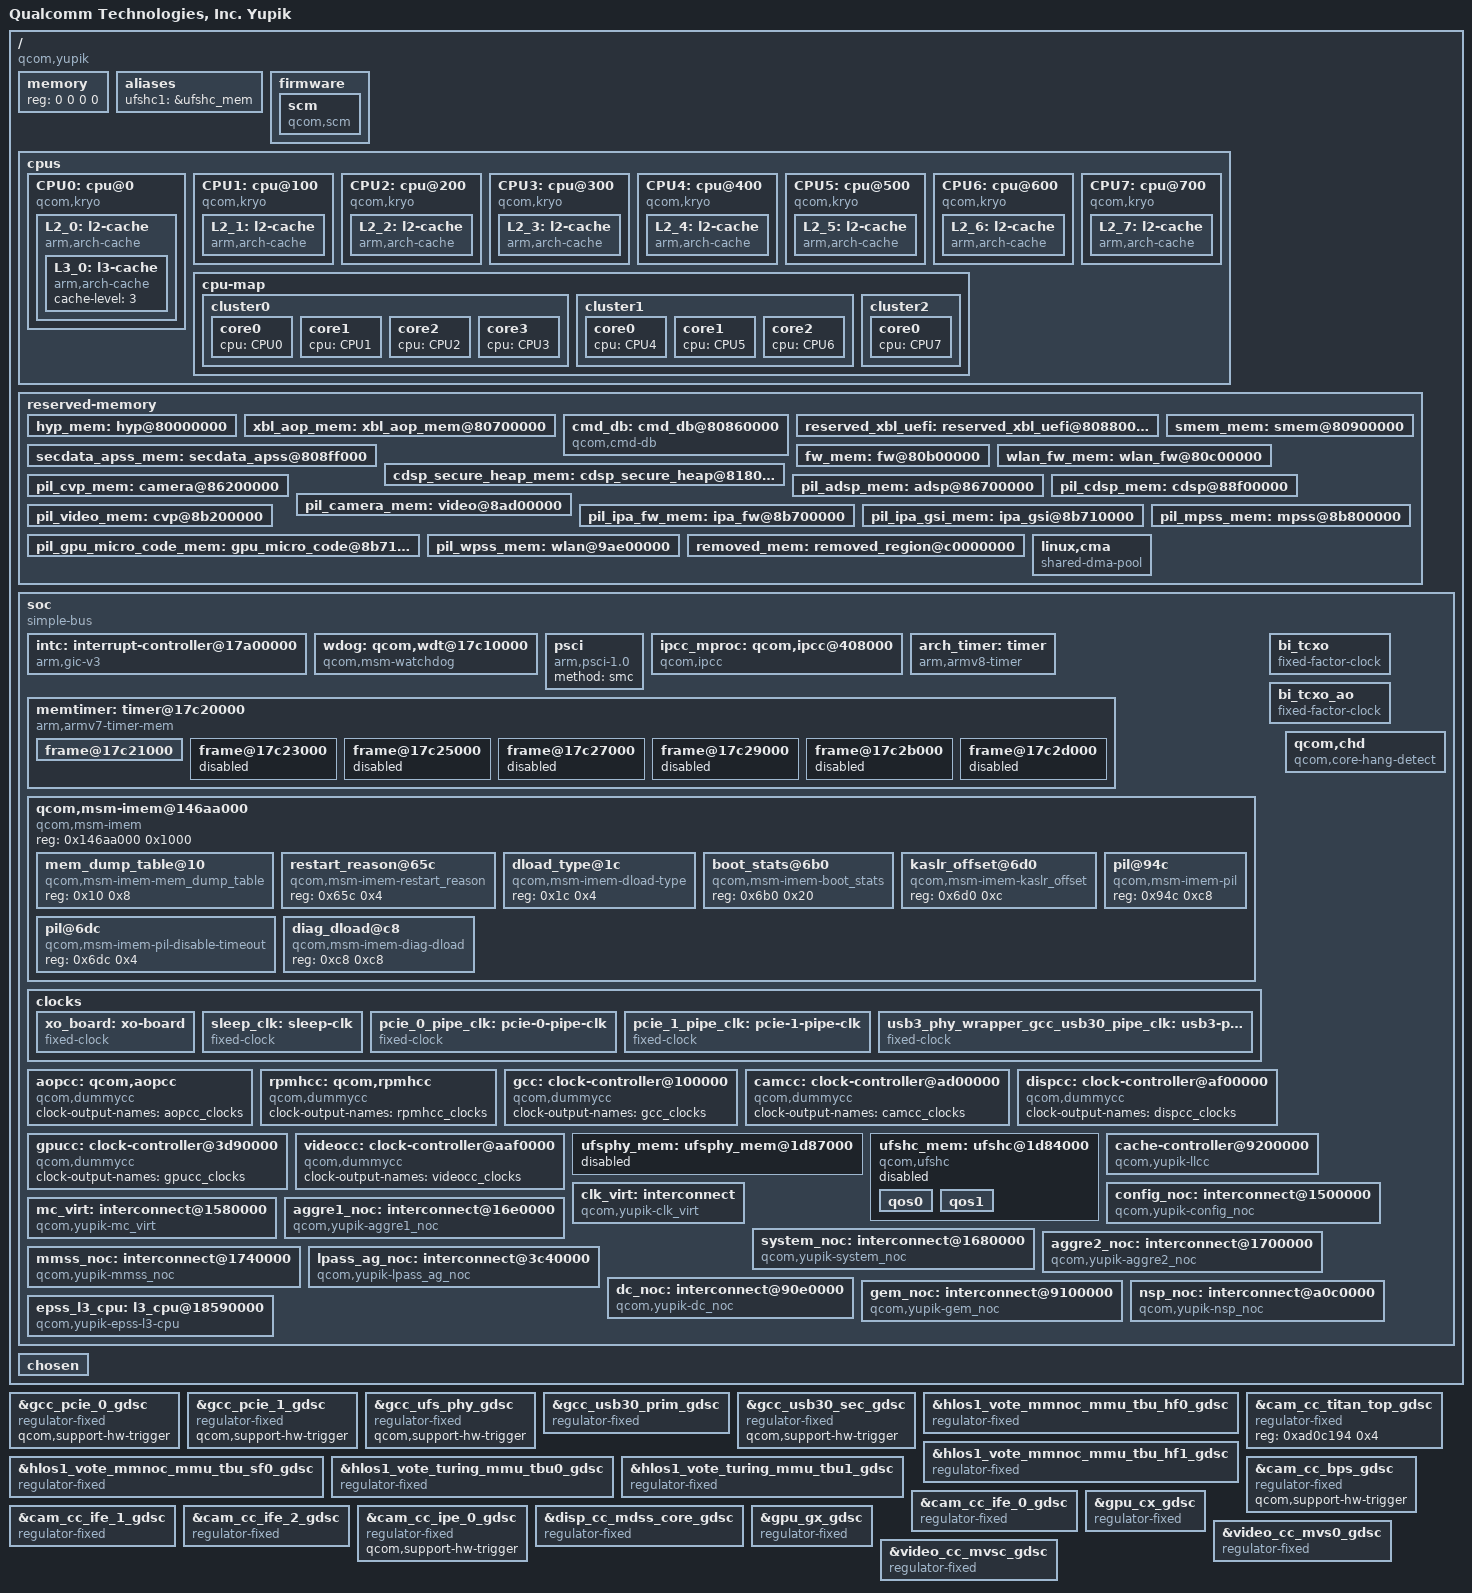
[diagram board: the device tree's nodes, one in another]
#include <dt-bindings/clock/qcom,aop-qmp.h>
#include <dt-bindings/clock/qcom,camcc-yupik.h>
#include <dt-bindings/clock/qcom,dispcc-yupik.h>
#include <dt-bindings/clock/qcom,gcc-yupik.h>
#include <dt-bindings/clock/qcom,gpucc-yupik.h>
#include <dt-bindings/clock/qcom,rpmh.h>
#include <dt-bindings/clock/qcom,videocc-yupik.h>
#include <dt-bindings/interconnect/qcom,epss-l3.h>
#include <dt-bindings/interconnect/qcom,icc.h>
#include <dt-bindings/interconnect/qcom,yupik.h>
#include <dt-bindings/interrupt-controller/arm-gic.h>
#include <dt-bindings/soc/qcom,ipcc.h>
#include <dt-bindings/gpio/gpio.h>

/ {
	model = "Qualcomm Technologies, Inc. Yupik";
	compatible = "qcom,yupik";
	qcom,msm-id = <475 0x10000>;
	interrupt-parent = <&intc>;

	#address-cells = <2>;
	#size-cells = <2>;
	memory { device_type = "memory"; reg = <0 0 0 0>; };

	aliases {
		ufshc1 = &ufshc_mem; /* Embedded UFS Slot */
	};

	firmware: firmware {
		scm {
			compatible = "qcom,scm";
		};
	};

	cpus {
		#address-cells = <2>;
		#size-cells = <0>;

		CPU0: cpu@0 {
			device_type = "cpu";
			compatible = "qcom,kryo";
			reg = <0x0 0x0>;
			enable-method = "psci";
			next-level-cache = <&L2_0>;
			L2_0: l2-cache {
			      compatible = "arm,arch-cache";
			      cache-level = <2>;
			      next-level-cache = <&L3_0>;

				L3_0: l3-cache {
				      compatible = "arm,arch-cache";
				      cache-level = <3>;
				};
			};
		};

		CPU1: cpu@100 {
			device_type = "cpu";
			compatible = "qcom,kryo";
			reg = <0x0 0x100>;
			enable-method = "psci";
			next-level-cache = <&L2_1>;
			L2_1: l2-cache {
			      compatible = "arm,arch-cache";
			      cache-level = <2>;
			      next-level-cache = <&L3_0>;
			};
		};

		CPU2: cpu@200 {
			device_type = "cpu";
			compatible = "qcom,kryo";
			reg = <0x0 0x200>;
			enable-method = "psci";
			next-level-cache = <&L2_2>;
			L2_2: l2-cache {
			      compatible = "arm,arch-cache";
			      cache-level = <2>;
			      next-level-cache = <&L3_0>;
			};
		};

		CPU3: cpu@300 {
			device_type = "cpu";
			compatible = "qcom,kryo";
			reg = <0x0 0x300>;
			enable-method = "psci";
			next-level-cache = <&L2_3>;
			L2_3: l2-cache {
			      compatible = "arm,arch-cache";
			      cache-level = <2>;
			      next-level-cache = <&L3_0>;
			};
		};

		CPU4: cpu@400 {
			device_type = "cpu";
			compatible = "qcom,kryo";
			reg = <0x0 0x400>;
			enable-method = "psci";
			next-level-cache = <&L2_4>;
			L2_4: l2-cache {
			      compatible = "arm,arch-cache";
			      cache-level = <2>;
			      next-level-cache = <&L3_0>;
			};
		};

		CPU5: cpu@500 {
			device_type = "cpu";
			compatible = "qcom,kryo";
			reg = <0x0 0x500>;
			enable-method = "psci";
			next-level-cache = <&L2_5>;
			L2_5: l2-cache {
			      compatible = "arm,arch-cache";
			      cache-level = <2>;
			      next-level-cache = <&L3_0>;
			};
		};

		CPU6: cpu@600 {
			device_type = "cpu";
			compatible = "qcom,kryo";
			reg = <0x0 0x600>;
			enable-method = "psci";
			next-level-cache = <&L2_6>;
			L2_6: l2-cache {
			      compatible = "arm,arch-cache";
			      cache-level = <2>;
			      next-level-cache = <&L3_0>;
			};
		};

		CPU7: cpu@700 {
			device_type = "cpu";
			compatible = "qcom,kryo";
			reg = <0x0 0x700>;
			enable-method = "psci";
			next-level-cache = <&L2_7>;
			L2_7: l2-cache {
			      compatible = "arm,arch-cache";
			      cache-level = <2>;
			      next-level-cache = <&L3_0>;
			};
		};

		cpu-map {
			cluster0 {
				core0 {
					cpu = <&CPU0>;
				};

				core1 {
					cpu = <&CPU1>;
				};

				core2 {
					cpu = <&CPU2>;
				};

				core3 {
					cpu = <&CPU3>;
				};
			};

			cluster1 {
				core0 {
					cpu = <&CPU4>;
				};

				core1 {
					cpu = <&CPU5>;
				};

				core2 {
					cpu = <&CPU6>;
				};
			};

			cluster2 {

				core0 {
					cpu = <&CPU7>;
				};
			};
		};
	};

	reserved-memory {
		#address-cells = <2>;
		#size-cells = <2>;
		ranges;

		hyp_mem: hyp@80000000 {
			no-map;
			reg = <0x0 0x80000000 0x0 0x600000>;
		};

		xbl_aop_mem: xbl_aop_mem@80700000 {
			no-map;
			reg = <0x0 0x80700000 0x0 0x160000>;
		};

		cmd_db: cmd_db@80860000 {
			compatible = "qcom,cmd-db";
			no-map;
			reg = <0x0 0x80860000 0x0 0x20000>;
		};

		reserved_xbl_uefi: reserved_xbl_uefi@80880000 {
			no-map;
			reg = <0x0 0x80880000 0x0 0x14000>;
		};

		secdata_apss_mem: secdata_apss@808ff000 {
			no-map;
			reg = <0x0 0x808ff000 0x0 0x1000>;
		};

		smem_mem: smem@80900000 {
			no-map;
			reg = <0x0 0x80900000 0x0 0x200000>;
		};

		fw_mem: fw@80b00000 {
			no-map;
			reg = <0x0 0x80b00000 0x0 0x100000>;
		};

		wlan_fw_mem: wlan_fw@80c00000 {
			no-map;
			reg = <0x0 0x80c00000 0x0 0xc00000>;
		};

		cdsp_secure_heap_mem: cdsp_secure_heap@81800000 {
			no-map;
			reg = <0x0 0x81800000 0x0 0x1e00000>;
		};

		pil_cvp_mem: camera@86200000 {
			no-map;
			reg = <0x0 0x86200000 0x0 0x500000>;
		};

		pil_adsp_mem: adsp@86700000 {
			no-map;
			reg = <0x0 0x86700000 0x0 0x2800000>;
		};

		pil_cdsp_mem: cdsp@88f00000 {
			no-map;
			reg = <0x0 0x88f00000 0x0 0x1e00000>;
		};

		pil_camera_mem: video@8ad00000 {
			no-map;
			reg = <0x0 0x8ad00000 0x0 0x500000>;
		};

		pil_video_mem: cvp@8b200000 {
			no-map;
			reg = <0x0 0x8b200000 0x0 0x500000>;
		};

		pil_ipa_fw_mem: ipa_fw@8b700000 {
			no-map;
			reg = <0x0 0x8b700000 0x0 0x10000>;
		};

		pil_ipa_gsi_mem: ipa_gsi@8b710000 {
			no-map;
			reg = <0x0 0x8b710000 0x0 0xa000>;
		};

		pil_gpu_micro_code_mem: gpu_micro_code@8b71a000 {
			no-map;
			reg = <0x0 0x8b71a000 0x0 0x2000>;
		};

		pil_mpss_mem: mpss@8b800000 {
			no-map;
			reg = <0x0 0x8b800000 0x0 0xf600000>;
		};

		pil_wpss_mem: wlan@9ae00000 {
			no-map;
			reg = <0x0 0x9ae00000 0x0 0x1900000>;
		};

		removed_mem: removed_region@c0000000 {
			no-map;
			reg = <0x0 0xc0000000 0x0 0x5100000>;
		};

		/* global autoconfigured region for contiguous allocations */
		linux,cma {
			compatible = "shared-dma-pool";
			alloc-ranges = <0x0 0x00000000 0x0 0xffffffff>;
			reusable;
			alignment = <0x0 0x400000>;
			size = <0x0 0x2000000>;
			linux,cma-default;
		};
	};

	soc: soc { };

	chosen { };
};

&soc {
	#address-cells = <1>;
	#size-cells = <1>;
	ranges = <0 0 0 0xffffffff>;
	compatible = "simple-bus";

	intc: interrupt-controller@17a00000 {
		compatible = "arm,gic-v3";
		#interrupt-cells = <3>;
		interrupt-controller;
		#redistributor-regions = <1>;
		redistributor-stride = <0x0 0x20000>;
		reg = <0x17a00000 0x10000>,     /* GICD */
		      <0x17a60000 0x100000>;    /* GICR * 8 */
		interrupts = <GIC_PPI 9 IRQ_TYPE_LEVEL_LOW>;
	};

	wdog: qcom,wdt@17c10000 {
		compatible = "qcom,msm-watchdog";
		reg = <0x17c10000 0x1000>;
		reg-names = "wdt-base";
		interrupts = <GIC_SPI 0 IRQ_TYPE_LEVEL_HIGH>;
	};

	psci {
		compatible = "arm,psci-1.0";
		method = "smc";
	};

	ipcc_mproc: qcom,ipcc@408000 {
		compatible = "qcom,ipcc";
		reg = <0x408000 0x1000>;
		interrupts = <GIC_SPI 229 IRQ_TYPE_LEVEL_HIGH>;
		interrupt-controller;
		#interrupt-cells = <3>;
		#mbox-cells = <2>;
	};

	arch_timer: timer {
		compatible = "arm,armv8-timer";
		interrupts = <GIC_PPI 13 (GIC_CPU_MASK_SIMPLE(8) | IRQ_TYPE_LEVEL_LOW)>,
			     <GIC_PPI 14 (GIC_CPU_MASK_SIMPLE(8) | IRQ_TYPE_LEVEL_LOW)>,
			     <GIC_PPI 11 (GIC_CPU_MASK_SIMPLE(8) | IRQ_TYPE_LEVEL_LOW)>,
			     <GIC_PPI 12 (GIC_CPU_MASK_SIMPLE(8) | IRQ_TYPE_LEVEL_LOW)>;
		clock-frequency = <19200000>;
	};

	memtimer: timer@17c20000 {
		#address-cells = <1>;
		#size-cells = <1>;
		ranges;
		compatible = "arm,armv7-timer-mem";
		reg = <0x17c20000 0x1000>;
		clock-frequency = <19200000>;

		frame@17c21000 {
			frame-number = <0>;
			interrupts = <GIC_SPI 8 IRQ_TYPE_LEVEL_HIGH>,
				     <GIC_SPI 6 IRQ_TYPE_LEVEL_HIGH>;
			reg = <0x17c21000 0x1000>,
			      <0x17c22000 0x1000>;
		};

		frame@17c23000 {
			frame-number = <1>;
			interrupts = <GIC_SPI 9 IRQ_TYPE_LEVEL_HIGH>;
			reg = <0x17c23000 0x1000>;
			status = "disabled";
		};

		frame@17c25000 {
			frame-number = <2>;
			interrupts = <GIC_SPI 10 IRQ_TYPE_LEVEL_HIGH>;
			reg = <0x17c25000 0x1000>;
			status = "disabled";
		};

		frame@17c27000 {
			frame-number = <3>;
			interrupts = <GIC_SPI 11 IRQ_TYPE_LEVEL_HIGH>;
			reg = <0x17c27000 0x1000>;
			status = "disabled";
		};

		frame@17c29000 {
			frame-number = <4>;
			interrupts = <GIC_SPI 12 IRQ_TYPE_LEVEL_HIGH>;
			reg = <0x17c29000 0x1000>;
			status = "disabled";
		};

		frame@17c2b000 {
			frame-number = <5>;
			interrupts = <GIC_SPI 13 IRQ_TYPE_LEVEL_HIGH>;
			reg = <0x17c2b000 0x1000>;
			status = "disabled";
		};

		frame@17c2d000 {
			frame-number = <6>;
			interrupts = <GIC_SPI 14 IRQ_TYPE_LEVEL_HIGH>;
			reg = <0x17c2d000 0x1000>;
			status = "disabled";
		};
	};

	qcom,msm-imem@146aa000 {
		compatible = "qcom,msm-imem";
		reg = <0x146aa000 0x1000>;
		ranges = <0x0 0x146aa000 0x1000>;
		#address-cells = <1>;
		#size-cells = <1>;

		mem_dump_table@10 {
			compatible = "qcom,msm-imem-mem_dump_table";
			reg = <0x10 0x8>;
		};

		restart_reason@65c {
			compatible = "qcom,msm-imem-restart_reason";
			reg = <0x65c 0x4>;
		};

		dload_type@1c {
			compatible = "qcom,msm-imem-dload-type";
			reg = <0x1c 0x4>;
		};

		boot_stats@6b0 {
			compatible = "qcom,msm-imem-boot_stats";
			reg = <0x6b0 0x20>;
		};

		kaslr_offset@6d0 {
			compatible = "qcom,msm-imem-kaslr_offset";
			reg = <0x6d0 0xc>;
		};

		pil@94c {
			compatible = "qcom,msm-imem-pil";
			reg = <0x94c 0xc8>;
		};

		pil@6dc {
			compatible = "qcom,msm-imem-pil-disable-timeout";
			reg = <0x6dc 0x4>;
		};

		diag_dload@c8 {
			compatible = "qcom,msm-imem-diag-dload";
			reg = <0xc8 0xc8>;
		};
	};

	clocks {
		xo_board: xo-board {
			compatible = "fixed-clock";
			clock-frequency = <76800000>;
			clock-output-names = "xo_board";
			#clock-cells = <0>;
		};

		sleep_clk: sleep-clk {
			compatible = "fixed-clock";
			clock-frequency = <32000>;
			clock-output-names = "sleep_clk";
			#clock-cells = <0>;
		};

		pcie_0_pipe_clk: pcie-0-pipe-clk {
			compatible = "fixed-clock";
			clock-frequency = <1000>;
			clock-output-names = "pcie_0_pipe_clk";
			#clock-cells = <0>;
		};

		pcie_1_pipe_clk: pcie-1-pipe-clk {
			compatible = "fixed-clock";
			clock-frequency = <1000>;
			clock-output-names = "pcie_1_pipe_clk";
			#clock-cells = <0>;
		};

		usb3_phy_wrapper_gcc_usb30_pipe_clk: usb3-phy-wrapper-gcc-usb30-pipe-clk {
			compatible = "fixed-clock";
			clock-frequency = <1000>;
			clock-output-names = "usb3_phy_wrapper_gcc_usb30_pipe_clk";
			#clock-cells = <0>;
		};
	};

	bi_tcxo: bi_tcxo {
		compatible = "fixed-factor-clock";
		clock-mult = <1>;
		clock-div = <4>;
		clocks = <&xo_board>;
		#clock-cells = <0>;
	};

	bi_tcxo_ao: bi_tcxo_ao {
		compatible = "fixed-factor-clock";
		clock-mult = <1>;
		clock-div = <4>;
		clocks = <&xo_board>;
		#clock-cells = <0>;
	};

	aopcc: qcom,aopcc {
		compatible = "qcom,dummycc";
		clock-output-names = "aopcc_clocks";
		#clock-cells = <1>;
		#reset-cells = <1>;
	};

	rpmhcc: qcom,rpmhcc {
		compatible = "qcom,dummycc";
		clock-output-names = "rpmhcc_clocks";
		#clock-cells = <1>;
		#reset-cells = <1>;
	};

	gcc: clock-controller@100000 {
		compatible = "qcom,dummycc";
		clock-output-names = "gcc_clocks";
		#clock-cells = <1>;
		#reset-cells = <1>;
	};

	camcc: clock-controller@ad00000 {
		compatible = "qcom,dummycc";
		clock-output-names = "camcc_clocks";
		#clock-cells = <1>;
		#reset-cells = <1>;
	};

	dispcc: clock-controller@af00000 {
		compatible = "qcom,dummycc";
		clock-output-names = "dispcc_clocks";
		#clock-cells = <1>;
		#reset-cells = <1>;
	};

	gpucc: clock-controller@3d90000 {
		compatible = "qcom,dummycc";
		clock-output-names = "gpucc_clocks";
		#clock-cells = <1>;
		#reset-cells = <1>;
	};

	videocc: clock-controller@aaf0000 {
		compatible = "qcom,dummycc";
		clock-output-names = "videocc_clocks";
		#clock-cells = <1>;
		#reset-cells = <1>;
	};

	ufsphy_mem: ufsphy_mem@1d87000 {
		reg = <0x1d87000 0xe00>;
		reg-names = "phy_mem";
		#phy-cells = <0>;

		lanes-per-direction = <2>;
		clock-names = "ref_clk_src",
			"ref_clk",
			"ref_aux_clk";
		clocks = <&rpmhcc RPMH_CXO_CLK>,
			<&gcc GCC_UFS_1_CLKREF_EN>,
			<&gcc GCC_UFS_PHY_PHY_AUX_CLK>;
		resets = <&ufshc_mem 0>;

		status = "disabled";
	};

	ufshc_mem: ufshc@1d84000 {
		compatible = "qcom,ufshc";
		reg = <0x1d84000 0x3000>;
		reg-names = "ufs_mem";
		interrupts = <GIC_SPI 265 IRQ_TYPE_LEVEL_HIGH>;
		phys = <&ufsphy_mem>;
		phy-names = "ufsphy";
		#reset-cells = <1>;

		lanes-per-direction = <2>;
		dev-ref-clk-freq = <0>; /* 19.2 MHz */
		clock-names =
			"core_clk",
			"bus_aggr_clk",
			"iface_clk",
			"core_clk_unipro",
			"core_clk_ice",
			"ref_clk",
			"tx_lane0_sync_clk",
			"rx_lane0_sync_clk",
			"rx_lane1_sync_clk";
		clocks =
			<&gcc GCC_UFS_PHY_AXI_CLK>,
			<&gcc GCC_AGGRE_UFS_PHY_AXI_CLK>,
			<&gcc GCC_UFS_PHY_AHB_CLK>,
			<&gcc GCC_UFS_PHY_UNIPRO_CORE_CLK>,
			<&gcc GCC_UFS_PHY_ICE_CORE_CLK>,
			<&rpmhcc RPMH_CXO_CLK>,
			<&gcc GCC_UFS_PHY_TX_SYMBOL_0_CLK>,
			<&gcc GCC_UFS_PHY_RX_SYMBOL_0_CLK>,
			<&gcc GCC_UFS_PHY_RX_SYMBOL_1_CLK>;
		freq-table-hz =
			<75000000 300000000>,
			<0 0>,
			<0 0>,
			<75000000 300000000>,
			<75000000 300000000>,
			<0 0>,
			<0 0>,
			<0 0>,
			<0 0>;

		qcom,ufs-bus-bw,name = "ufshc_mem";
		qcom,ufs-bus-bw,num-cases = <26>;
		qcom,ufs-bus-bw,num-paths = <2>;
		qcom,ufs-bus-bw,vectors-KBps =
		/*
		 * During HS G3 UFS runs at nominal voltage corner, vote
		 * higher bandwidth to push other buses in the data path
		 * to run at nominal to achieve max throughput.
		 * 4GBps pushes BIMC to run at nominal.
		 * 200MBps pushes CNOC to run at nominal.
		 * Vote for half of this bandwidth for HS G3 1-lane.
		 * For max bandwidth, vote high enough to push the buses
		 * to run in turbo voltage corner.
		 */
		<0 0>, <0 0>,          /* No vote */
		<922 0>, <1000 0>,     /* PWM G1 */
		<1844 0>, <1000 0>,    /* PWM G2 */
		<3688 0>, <1000 0>,    /* PWM G3 */
		<7376 0>, <1000 0>,    /* PWM G4 */
		<1844 0>, <1000 0>,    /* PWM G1 L2 */
		<3688 0>, <1000 0>,    /* PWM G2 L2 */
		<7376 0>, <1000 0>,    /* PWM G3 L2 */
		<14752 0>, <1000 0>,   /* PWM G4 L2 */
		<127796 0>, <1000 0>,  /* HS G1 RA */
		<255591 0>, <1000 0>,  /* HS G2 RA */
		<2097152 0>, <102400 0>,  /* HS G3 RA */
		<4194304 0>, <204800 0>,  /* HS G4 RA */
		<255591 0>, <1000 0>,  /* HS G1 RA L2 */
		<511181 0>, <1000 0>,  /* HS G2 RA L2 */
		<4194304 0>, <204800 0>, /* HS G3 RA L2 */
		<8388608 0>, <409600 0>, /* HS G4 RA L2 */
		<149422 0>, <1000 0>,  /* HS G1 RB */
		<298189 0>, <1000 0>,  /* HS G2 RB */
		<2097152 0>, <102400 0>,  /* HS G3 RB */
		<4194304 0>, <204800 0>,  /* HS G4 RB */
		<298189 0>, <1000 0>,  /* HS G1 RB L2 */
		<596378 0>, <1000 0>,  /* HS G2 RB L2 */
		/* As UFS working in HS G3 RB L2 mode, aggregated
		 * bandwidth (AB) should take care of providing
		 * optimum throughput requested. However, as tested,
		 * in order to scale up CNOC clock, instantaneous
		 * bindwidth (IB) needs to be given a proper value too.
		 */
		<4194304 0>, <204800 409600>, /* HS G3 RB L2 */
		<8388608 0>, <409600 409600>, /* HS G4 RB L2 */
		<7643136 0>, <307200 0>; /* Max. bandwidth */

		qcom,bus-vector-names = "MIN",
		"PWM_G1_L1", "PWM_G2_L1", "PWM_G3_L1", "PWM_G4_L1",
		"PWM_G1_L2", "PWM_G2_L2", "PWM_G3_L2", "PWM_G4_L2",
		"HS_RA_G1_L1", "HS_RA_G2_L1", "HS_RA_G3_L1", "HS_RA_G4_L1",
		"HS_RA_G1_L2", "HS_RA_G2_L2", "HS_RA_G3_L2", "HS_RA_G4_L2",
		"HS_RB_G1_L1", "HS_RB_G2_L1", "HS_RB_G3_L1", "HS_RB_G4_L1",
		"HS_RB_G1_L2", "HS_RB_G2_L2", "HS_RB_G3_L2", "HS_RB_G4_L2",
		"MAX";

		reset-gpios = <&tlmm 175 GPIO_ACTIVE_LOW>;
		resets = <&gcc GCC_UFS_PHY_BCR>;
		reset-names = "rst";

		rpm-level = <3>;
		spm-level = <3>;

		status = "disabled";

		qos0 {
			mask = <0xf0>;
			vote = <59>;
		};

		qos1 {
			mask = <0x0f>;
			vote = <65>;
		};
	};

	qcom,chd {
		compatible = "qcom,core-hang-detect";
		label = "core";
		qcom,threshold-arr = <0x18000058 0x18010058 0x18020058 0x18030058
				0x18040058 0x18050058 0x18060058 0x18070058>;
		qcom,config-arr = <0x18000060 0x18010060 0x18020060 0x18030060
				0x18040060 0x18050060 0x18060060 0x18070060>;
	};

	cache-controller@9200000 {
		compatible = "qcom,yupik-llcc","qcom,llcc-v2";
		reg = <0x9200000 0xd0000>, <0x9600000 0x50000>;
		reg-names = "llcc_base", "llcc_broadcast_base";
		cap-based-alloc-and-pwr-collapse;
		clocks = <&aopcc QDSS_CLK>;
		clock-names = "qdss_clk";
	};

	clk_virt: interconnect {
		compatible = "qcom,yupik-clk_virt";
		#interconnect-cells = <1>;
	};

	config_noc: interconnect@1500000 {
		compatible = "qcom,yupik-config_noc";
		#interconnect-cells = <1>;
	};

	mc_virt: interconnect@1580000 {
		compatible = "qcom,yupik-mc_virt";
		#interconnect-cells = <1>;
	};

	system_noc: interconnect@1680000 {
		compatible = "qcom,yupik-system_noc";
		#interconnect-cells = <1>;
	};

	aggre1_noc: interconnect@16e0000 {
		compatible = "qcom,yupik-aggre1_noc";
		#interconnect-cells = <1>;
	};

	aggre2_noc: interconnect@1700000 {
		compatible = "qcom,yupik-aggre2_noc";
		#interconnect-cells = <1>;
	};

	mmss_noc: interconnect@1740000 {
		compatible = "qcom,yupik-mmss_noc";
		#interconnect-cells = <1>;
	};

	lpass_ag_noc: interconnect@3c40000 {
		compatible = "qcom,yupik-lpass_ag_noc";
		#interconnect-cells = <1>;
	};

	dc_noc: interconnect@90e0000 {
		compatible = "qcom,yupik-dc_noc";
		#interconnect-cells = <1>;
	};

	gem_noc: interconnect@9100000 {
		compatible = "qcom,yupik-gem_noc";
		#interconnect-cells = <1>;
	};

	nsp_noc: interconnect@a0c0000 {
		compatible = "qcom,yupik-nsp_noc";
		#interconnect-cells = <1>;
	};

	epss_l3_cpu: l3_cpu@18590000 {
		compatible = "qcom,yupik-epss-l3-cpu";
		#interconnect-cells = <1>;
	};
};

#include "shima-gdsc.dtsi"
#include "yupik-pinctrl.dtsi"
#include "yupik-stub-regulator.dtsi"
#include "ipcc-test-yupik.dtsi"

&gcc_pcie_0_gdsc {
	compatible = "regulator-fixed";
	qcom,support-hw-trigger;
	status = "ok";
};

&gcc_pcie_1_gdsc {
	compatible = "regulator-fixed";
	qcom,support-hw-trigger;
	status = "ok";
};

&gcc_ufs_phy_gdsc {
	compatible = "regulator-fixed";
	qcom,support-hw-trigger;
	status = "ok";
};

&gcc_usb30_prim_gdsc {
	compatible = "regulator-fixed";
	status = "ok";
};

&gcc_usb30_sec_gdsc {
	compatible = "regulator-fixed";
	qcom,support-hw-trigger;
	status = "ok";
};

&hlos1_vote_mmnoc_mmu_tbu_hf0_gdsc {
	compatible = "regulator-fixed";
	status = "ok";
};

&hlos1_vote_mmnoc_mmu_tbu_hf1_gdsc {
	compatible = "regulator-fixed";
	status = "ok";
};

&hlos1_vote_mmnoc_mmu_tbu_sf0_gdsc {
	compatible = "regulator-fixed";
	status = "ok";
};

&hlos1_vote_turing_mmu_tbu0_gdsc {
	compatible = "regulator-fixed";
	status = "ok";
};

&hlos1_vote_turing_mmu_tbu1_gdsc {
	compatible = "regulator-fixed";
	status = "ok";
};

&cam_cc_titan_top_gdsc {
	compatible = "regulator-fixed";
	reg = <0xad0c194 0x4>;
	status = "ok";
};

&cam_cc_bps_gdsc {
	compatible = "regulator-fixed";
	qcom,support-hw-trigger;
	status = "ok";
};

&cam_cc_ife_0_gdsc {
	compatible = "regulator-fixed";
	status = "ok";
};

&cam_cc_ife_1_gdsc {
	compatible = "regulator-fixed";
	status = "ok";
};

&cam_cc_ife_2_gdsc {
	compatible = "regulator-fixed";
	status = "ok";
};

&cam_cc_ipe_0_gdsc {
	compatible = "regulator-fixed";
	qcom,support-hw-trigger;
	status = "ok";
};

&disp_cc_mdss_core_gdsc {
	compatible = "regulator-fixed";
	reg = <0xaf01004 0x4>;
	qcom,support-hw-trigger;
	status = "ok";
};

&gpu_cx_gdsc {
	compatible = "regulator-fixed";
	status = "ok";
};

&gpu_gx_gdsc {
	compatible = "regulator-fixed";
	status = "ok";
};

&video_cc_mvs0_gdsc {
	compatible = "regulator-fixed";
	reg = <0xaaf3004 0x4>;
	qcom,support-hw-trigger;
	status = "ok";
};

&video_cc_mvsc_gdsc {
	compatible = "regulator-fixed";
	status = "ok";
};
